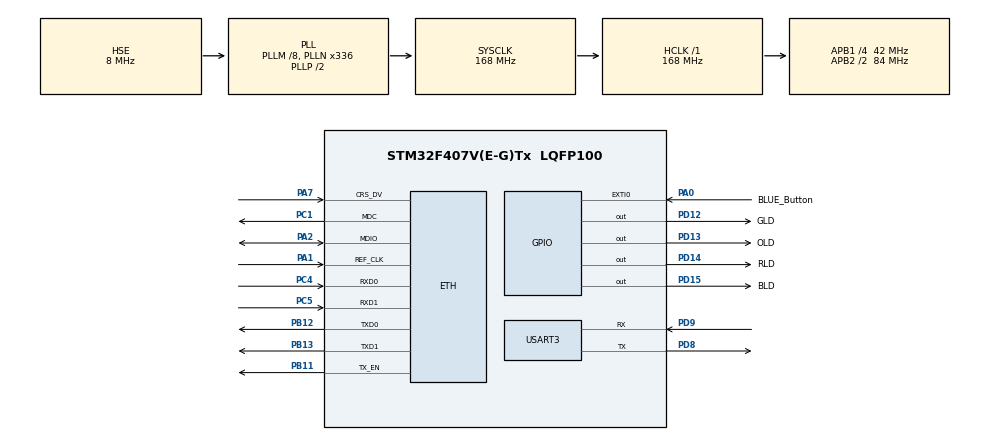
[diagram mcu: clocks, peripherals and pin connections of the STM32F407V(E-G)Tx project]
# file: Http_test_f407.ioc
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Mcu.Family=STM32F4
RCC.PLLSourceVirtual=RCC_PLLSOURCE_HSE
PD12.GPIO_Label=GLD
PH0-OSC_IN.Signal=RCC_OSC_IN
RCC.CortexFreq_Value=168000000
PD15.GPIO_Label=BLD
PA7.Mode=RMII
PC4.Signal=ETH_RXD0
PD9.Signal=USART3_RX
LWIP.LWIP_DHCP=0
PC5.Mode=RMII
RCC.APB1CLKDivider=RCC_HCLK_DIV4
PB11.Signal=ETH_TX_EN
PB13.Signal=ETH_TXD1
PD9.Mode=Asynchronous
RCC.SYSCLKSource=RCC_SYSCLKSOURCE_PLLCLK
ProjectManager.StackSize=0x400
PA0-WKUP.GPIO_Label=BLUE_Button
PA0-WKUP.Signal=GPXTI0
VP_LWIP_VS_Enabled.Mode=Enabled
LWIP.LWIP_DNS=1
LWIP.LWIP_HTTPD=1
PD13.Signal=GPIO_Output
PA13.Signal=SYS_JTMS-SWDIO
PB11.Mode=RMII
ProjectManager.TargetToolchain=TrueSTUDIO
RCC.HCLKFreq_Value=168000000
RCC.APB2TimFreq_Value=168000000
PD8.Signal=USART3_TX
PD8.Mode=Asynchronous
PA1.Signal=ETH_REF_CLK
RCC.AHBFreq_Value=168000000
PH0-OSC_IN.Mode=HSE-External-Oscillator
RCC.HSE_VALUE=8000000
board=STM32F407G-DISC1
RCC.VCOOutputFreq_Value=336000000
RCC.APB2Freq_Value=84000000
PA1.Mode=RMII
PA14.Mode=Serial_Wire
PH1-OSC_OUT.Signal=RCC_OSC_OUT
PD14.GPIO_Label=RLD
PA13.Mode=Serial_Wire
Mcu.Name=STM32F407V(E-G)Tx
PA2.Signal=ETH_MDIO
PD14.Signal=GPIO_Output
PH1-OSC_OUT.Mode=HSE-External-Oscillator
RCC.48MHZClocksFreq_Value=48000000
PB3.Signal=SYS_JTDO-SWO
NVIC.EXTI0_IRQn=true\:0\:4\:false\:false\:true\:true\:true
RCC.SYSCLKFreq_VALUE=168000000
PD13.GPIO_Label=OLD
Mcu.Package=LQFP100
ETH.MediaInterface=ETH_MEDIA_INTERFACE_RMII
PB12.Mode=RMII
USART3.VirtualMode=VM_ASYNC
PD12.Signal=GPIO_Output
PA14.Signal=SYS_JTCK-SWCLK
ProjectManager.HeapSize=0x200
LWIP.Version=v2.1.2_Cube
RCC.HSI_VALUE=16000000
RCC.PLLQ=7
NVIC.PriorityGroup=NVIC_PRIORITYGROUP_0
RCC.APB2CLKDivider=RCC_HCLK_DIV2
RCC.PLLM=8
RCC.PLLN=336
RCC.APB1TimFreq_Value=84000000
PA2.Mode=RMII
PC5.Signal=ETH_RXD1
PB13.Mode=RMII
RCC.APB1Freq_Value=42000000
PD15.Signal=GPIO_Output
PC1.Signal=ETH_MDC
PB12.Signal=ETH_TXD0
PC4.Mode=RMII
PC1.Mode=RMII
PA7.Signal=ETH_CRS_DV

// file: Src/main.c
/* USER CODE BEGIN Header */
/**
  ******************************************************************************
  * @file           : main.c
  * @brief          : Main program body
  ******************************************************************************
  * @attention
  *
  * <h2><center>&copy; Copyright (c) 2020 STMicroelectronics.
  * All rights reserved.</center></h2>
  *
  * This software component is licensed by ST under Ultimate Liberty license
  * SLA0044, the "License"; You may not use this file except in compliance with
  * the License. You may obtain a copy of the License at:
  *                             www.st.com/SLA0044
  *
  ******************************************************************************
  */
/* USER CODE END Header */

#include "main.h"
#include "lwip.h"

/* USER CODE BEGIN Includes */
#include "lwip/apps/httpd.h"

/* USER CODE END Includes */

UART_HandleTypeDef huart3;

void SystemClock_Config(void);
static void MX_GPIO_Init(void);
static void MX_USART3_UART_Init(void);

int main(void)
{

  /* MCU Configuration--------------------------------------------------------*/

  /* Reset of all peripherals, Initializes the Flash interface and the Systick. */
  HAL_Init();

  /* Configure the system clock */
  SystemClock_Config();

  /* Initialize all configured peripherals */
  MX_GPIO_Init();
  MX_USART3_UART_Init();
  MX_LWIP_Init();
  /* USER CODE BEGIN 2 */
  httpd_init();

  /* USER CODE END 2 */

  /* Infinite loop */
  while (1)
  {

  }
}

void SystemClock_Config(void)
{
  RCC_OscInitTypeDef RCC_OscInitStruct = {0};
  RCC_ClkInitTypeDef RCC_ClkInitStruct = {0};

  /** Configure the main internal regulator output voltage
  */
  __HAL_RCC_PWR_CLK_ENABLE();
  __HAL_PWR_VOLTAGESCALING_CONFIG(PWR_REGULATOR_VOLTAGE_SCALE1);
  /** Initializes the CPU, AHB and APB busses clocks
  */
  RCC_OscInitStruct.OscillatorType = RCC_OSCILLATORTYPE_HSE;
  RCC_OscInitStruct.HSEState = RCC_HSE_ON;
  RCC_OscInitStruct.PLL.PLLState = RCC_PLL_ON;
  RCC_OscInitStruct.PLL.PLLSource = RCC_PLLSOURCE_HSE;
  RCC_OscInitStruct.PLL.PLLM = 8;
  RCC_OscInitStruct.PLL.PLLN = 336;
  RCC_OscInitStruct.PLL.PLLP = RCC_PLLP_DIV2;
  RCC_OscInitStruct.PLL.PLLQ = 7;
  if (HAL_RCC_OscConfig(&RCC_OscInitStruct) != HAL_OK)
  {
    Error_Handler();
  }
  /** Initializes the CPU, AHB and APB busses clocks
  */
  RCC_ClkInitStruct.ClockType = RCC_CLOCKTYPE_HCLK|RCC_CLOCKTYPE_SYSCLK
                              |RCC_CLOCKTYPE_PCLK1|RCC_CLOCKTYPE_PCLK2;
  RCC_ClkInitStruct.SYSCLKSource = RCC_SYSCLKSOURCE_PLLCLK;
  RCC_ClkInitStruct.AHBCLKDivider = RCC_SYSCLK_DIV1;
  RCC_ClkInitStruct.APB1CLKDivider = RCC_HCLK_DIV4;
  RCC_ClkInitStruct.APB2CLKDivider = RCC_HCLK_DIV2;

  if (HAL_RCC_ClockConfig(&RCC_ClkInitStruct, FLASH_LATENCY_5) != HAL_OK)
  {
    Error_Handler();
  }
}

static void MX_USART3_UART_Init(void)
{

  huart3.Instance = USART3;
  huart3.Init.BaudRate = 115200;
  huart3.Init.WordLength = UART_WORDLENGTH_8B;
  huart3.Init.StopBits = UART_STOPBITS_1;
  huart3.Init.Parity = UART_PARITY_NONE;
  huart3.Init.Mode = UART_MODE_TX_RX;
  huart3.Init.HwFlowCtl = UART_HWCONTROL_NONE;
  huart3.Init.OverSampling = UART_OVERSAMPLING_16;
  if (HAL_UART_Init(&huart3) != HAL_OK)
  {
    Error_Handler();
  }

}

static void MX_GPIO_Init(void)
{
  GPIO_InitTypeDef GPIO_InitStruct = {0};

  /* GPIO Ports Clock Enable */
  __HAL_RCC_GPIOH_CLK_ENABLE();
  __HAL_RCC_GPIOC_CLK_ENABLE();
  __HAL_RCC_GPIOA_CLK_ENABLE();
  __HAL_RCC_GPIOB_CLK_ENABLE();
  __HAL_RCC_GPIOD_CLK_ENABLE();

  /*Configure GPIO pin Output Level */
  HAL_GPIO_WritePin(GPIOD, GLD_Pin|OLD_Pin|RLD_Pin|BLD_Pin, GPIO_PIN_RESET);

  /*Configure GPIO pin : BLUE_Button_Pin */
  GPIO_InitStruct.Pin = BLUE_Button_Pin;
  GPIO_InitStruct.Mode = GPIO_MODE_IT_RISING;
  GPIO_InitStruct.Pull = GPIO_NOPULL;
  HAL_GPIO_Init(BLUE_Button_GPIO_Port, &GPIO_InitStruct);

  /*Configure GPIO pins : GLD_Pin OLD_Pin RLD_Pin BLD_Pin */
  GPIO_InitStruct.Pin = GLD_Pin|OLD_Pin|RLD_Pin|BLD_Pin;
  GPIO_InitStruct.Mode = GPIO_MODE_OUTPUT_PP;
  GPIO_InitStruct.Pull = GPIO_NOPULL;
  GPIO_InitStruct.Speed = GPIO_SPEED_FREQ_LOW;
  HAL_GPIO_Init(GPIOD, &GPIO_InitStruct);

  /* EXTI interrupt init*/
  HAL_NVIC_SetPriority(EXTI0_IRQn, 0, 4);
  HAL_NVIC_EnableIRQ(EXTI0_IRQn);

}

void Error_Handler(void)
{
}

/************************ (C) COPYRIGHT STMicroelectronics *****END OF FILE****/
